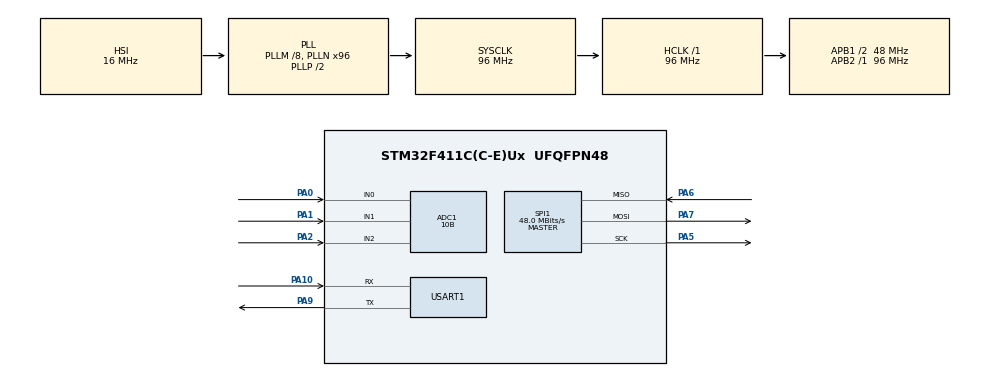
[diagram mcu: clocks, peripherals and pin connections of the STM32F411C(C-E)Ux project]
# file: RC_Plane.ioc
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ADC1.Channel-2\#ChannelRegularConversion=ADC_CHANNEL_0
ADC1.Channel-3\#ChannelRegularConversion=ADC_CHANNEL_1
ADC1.Channel-4\#ChannelRegularConversion=ADC_CHANNEL_2
ADC1.ContinuousConvMode=ENABLE
ADC1.DMAContinuousRequests=ENABLE
ADC1.EOCSelection=ADC_EOC_SEQ_CONV
ADC1.NbrOfConversion=3
ADC1.NbrOfConversionFlag=1
ADC1.Rank-2\#ChannelRegularConversion=1
ADC1.Rank-3\#ChannelRegularConversion=2
ADC1.Rank-4\#ChannelRegularConversion=3
ADC1.Resolution=ADC_RESOLUTION_10B
ADC1.SamplingTime-2\#ChannelRegularConversion=ADC_SAMPLETIME_84CYCLES
ADC1.SamplingTime-3\#ChannelRegularConversion=ADC_SAMPLETIME_84CYCLES
ADC1.SamplingTime-4\#ChannelRegularConversion=ADC_SAMPLETIME_84CYCLES
ADC1.ScanConvMode=ENABLE
ADC1.master=1
Dma.ADC1.0.Direction=DMA_PERIPH_TO_MEMORY
Dma.ADC1.0.FIFOMode=DMA_FIFOMODE_DISABLE
Dma.ADC1.0.Instance=DMA2_Stream0
Dma.ADC1.0.MemDataAlignment=DMA_MDATAALIGN_HALFWORD
Dma.ADC1.0.MemInc=DMA_MINC_ENABLE
Dma.ADC1.0.Mode=DMA_CIRCULAR
Dma.ADC1.0.PeriphDataAlignment=DMA_PDATAALIGN_HALFWORD
Dma.ADC1.0.PeriphInc=DMA_PINC_DISABLE
Dma.ADC1.0.Priority=DMA_PRIORITY_LOW
Dma.Request0=ADC1
FREERTOS.Tasks01=defaultTask,0,128,StartDefaultTask,Default,NULL,Dynamic,NULL,NULL
Mcu.Family=STM32F4
Mcu.Name=STM32F411C(C-E)Ux
Mcu.Package=UFQFPN48
NVIC.DMA2_Stream0_IRQn=true\:5\:0\:false\:false\:true\:true\:false\:true\:true
NVIC.PriorityGroup=NVIC_PRIORITYGROUP_4
NVIC.TIM1_TRG_COM_TIM11_IRQn=true\:15\:0\:false\:false\:true\:false\:false\:true\:true
NVIC.TimeBase=TIM1_TRG_COM_TIM11_IRQn
NVIC.TimeBaseIP=TIM11
PA0-WKUP.Signal=ADCx_IN0
PA1.Signal=ADCx_IN1
PA10.Mode=Asynchronous
PA10.Signal=USART1_RX
PA13.Mode=Serial_Wire
PA13.Signal=SYS_JTMS-SWDIO
PA14.Mode=Serial_Wire
PA14.Signal=SYS_JTCK-SWCLK
PA2.Signal=ADCx_IN2
PA5.Mode=Full_Duplex_Master
PA5.Signal=SPI1_SCK
PA6.Mode=Full_Duplex_Master
PA6.Signal=SPI1_MISO
PA7.Mode=Full_Duplex_Master
PA7.Signal=SPI1_MOSI
PA9.Mode=Asynchronous
PA9.Signal=USART1_TX
PH0\ -\ OSC_IN.Mode=HSE-External-Oscillator
PH0\ -\ OSC_IN.Signal=RCC_OSC_IN
PH1\ -\ OSC_OUT.Mode=HSE-External-Oscillator
PH1\ -\ OSC_OUT.Signal=RCC_OSC_OUT
ProjectManager.HeapSize=0x200
ProjectManager.StackSize=0x400
ProjectManager.TargetToolchain=CMake
RCC.48MHZClocksFreq_Value=48000000
RCC.AHBFreq_Value=96000000
RCC.APB1CLKDivider=RCC_HCLK_DIV2
RCC.APB1Freq_Value=48000000
RCC.APB1TimFreq_Value=96000000
RCC.APB2Freq_Value=96000000
RCC.APB2TimFreq_Value=96000000
RCC.CortexFreq_Value=96000000
RCC.HCLKFreq_Value=96000000
RCC.HSE_VALUE=25000000
RCC.HSI_VALUE=16000000
RCC.LSE_VALUE=32768
RCC.PLLM=8
RCC.PLLN=96
RCC.SYSCLKFreq_VALUE=96000000
RCC.SYSCLKSource=RCC_SYSCLKSOURCE_PLLCLK
RCC.VCOOutputFreq_Value=192000000
SH.ADCx_IN0.0=ADC1_IN0,IN0
SH.ADCx_IN1.0=ADC1_IN1,IN1
SH.ADCx_IN2.0=ADC1_IN2,IN2
SPI1.CalculateBaudRate=48.0 MBits/s
SPI1.Direction=SPI_DIRECTION_2LINES
SPI1.Mode=SPI_MODE_MASTER
SPI1.VirtualType=VM_MASTER
USART1.VirtualMode=VM_ASYNC
VP_FREERTOS_VS_CMSIS_V1.Mode=CMSIS_V1
VP_SYS_VS_tim11.Mode=TIM11
board=custom

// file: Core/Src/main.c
/* USER CODE BEGIN Header */
/**
  ******************************************************************************
  * @file           : main.c
  * @brief          : Main program body
  ******************************************************************************
  * @attention
  *
  * Copyright (c) 2026 STMicroelectronics.
  * All rights reserved.
  *
  * This software is licensed under terms that can be found in the LICENSE file
  * in the root directory of this software component.
  * If no LICENSE file comes with this software, it is provided AS-IS.
  *
  ******************************************************************************
  */
/* USER CODE END Header */
#include "main.h"
#include "cmsis_os.h"
#include "adc.h"
#include "dma.h"
#include "spi.h"
#include "usart.h"
#include "gpio.h"

/* USER CODE BEGIN PV */
volatile uint16_t joystick_vals[3];
/* USER CODE END PV */

void SystemClock_Config(void);
void MX_FREERTOS_Init(void);

int main(void)
{

  /* MCU Configuration--------------------------------------------------------*/

  /* Reset of all peripherals, Initializes the Flash interface and the Systick. */
  HAL_Init();

  /* Configure the system clock */
  SystemClock_Config();

  /* Initialize all configured peripherals */
  MX_GPIO_Init();
  MX_DMA_Init();
  MX_ADC1_Init();
  MX_SPI1_Init();
  MX_USART1_UART_Init();

  /* Call init function for freertos objects (in cmsis_os2.c) */
  MX_FREERTOS_Init();

  /* Start scheduler */
  osKernelStart();

  /* We should never get here as control is now taken by the scheduler */

  /* Infinite loop */
  while (1)
  {

  }
}

void SystemClock_Config(void)
{
  RCC_OscInitTypeDef RCC_OscInitStruct = {0};
  RCC_ClkInitTypeDef RCC_ClkInitStruct = {0};

  /** Configure the main internal regulator output voltage
  */
  __HAL_RCC_PWR_CLK_ENABLE();
  __HAL_PWR_VOLTAGESCALING_CONFIG(PWR_REGULATOR_VOLTAGE_SCALE1);

  /** Initializes the RCC Oscillators according to the specified parameters
  * in the RCC_OscInitTypeDef structure.
  */
  RCC_OscInitStruct.OscillatorType = RCC_OSCILLATORTYPE_HSI;
  RCC_OscInitStruct.HSIState = RCC_HSI_ON;
  RCC_OscInitStruct.HSICalibrationValue = RCC_HSICALIBRATION_DEFAULT;
  RCC_OscInitStruct.PLL.PLLState = RCC_PLL_ON;
  RCC_OscInitStruct.PLL.PLLSource = RCC_PLLSOURCE_HSI;
  RCC_OscInitStruct.PLL.PLLM = 8;
  RCC_OscInitStruct.PLL.PLLN = 96;
  RCC_OscInitStruct.PLL.PLLP = RCC_PLLP_DIV2;
  RCC_OscInitStruct.PLL.PLLQ = 4;
  if (HAL_RCC_OscConfig(&RCC_OscInitStruct) != HAL_OK)
  {
    Error_Handler();
  }

  /** Initializes the CPU, AHB and APB buses clocks
  */
  RCC_ClkInitStruct.ClockType = RCC_CLOCKTYPE_HCLK|RCC_CLOCKTYPE_SYSCLK
                              |RCC_CLOCKTYPE_PCLK1|RCC_CLOCKTYPE_PCLK2;
  RCC_ClkInitStruct.SYSCLKSource = RCC_SYSCLKSOURCE_PLLCLK;
  RCC_ClkInitStruct.AHBCLKDivider = RCC_SYSCLK_DIV1;
  RCC_ClkInitStruct.APB1CLKDivider = RCC_HCLK_DIV2;
  RCC_ClkInitStruct.APB2CLKDivider = RCC_HCLK_DIV1;

  if (HAL_RCC_ClockConfig(&RCC_ClkInitStruct, FLASH_LATENCY_3) != HAL_OK)
  {
    Error_Handler();
  }
}

void HAL_TIM_PeriodElapsedCallback(TIM_HandleTypeDef *htim)
{
  if (htim->Instance == TIM11)
  {
    HAL_IncTick();
  }
}

void Error_Handler(void)
{
  __disable_irq();
  while (1)
  {
  }
}

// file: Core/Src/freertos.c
/* USER CODE BEGIN Header */
/**
  ******************************************************************************
  * File Name          : freertos.c
  * Description        : Code for freertos applications
  ******************************************************************************
  * @attention
  *
  * Copyright (c) 2026 STMicroelectronics.
  * All rights reserved.
  *
  * This software is licensed under terms that can be found in the LICENSE file
  * in the root directory of this software component.
  * If no LICENSE file comes with this software, it is provided AS-IS.
  *
  ******************************************************************************
  */
/* USER CODE END Header */

#include "FreeRTOS.h"
#include "adc.h"
#include "joysticks.h"
#include "task.h"
#include "main.h"
#include "cmsis_os.h"
#include <stdint.h>
#include <stdio.h>

osThreadId defaultTaskHandle;

void StartDefaultTask(void const * argument);

void MX_FREERTOS_Init(void); /* (MISRA C 2004 rule 8.1) */

/* GetIdleTaskMemory prototype (linked to static allocation support) */
void vApplicationGetIdleTaskMemory( StaticTask_t **ppxIdleTaskTCBBuffer, StackType_t **ppxIdleTaskStackBuffer, uint32_t *pulIdleTaskStackSize );

/* USER CODE BEGIN GET_IDLE_TASK_MEMORY */
static StaticTask_t xIdleTaskTCBBuffer;
static StackType_t xIdleStack[configMINIMAL_STACK_SIZE];

void vApplicationGetIdleTaskMemory( StaticTask_t **ppxIdleTaskTCBBuffer, StackType_t **ppxIdleTaskStackBuffer, uint32_t *pulIdleTaskStackSize )
{
  *ppxIdleTaskTCBBuffer = &xIdleTaskTCBBuffer;
  *ppxIdleTaskStackBuffer = &xIdleStack[0];
  *pulIdleTaskStackSize = configMINIMAL_STACK_SIZE;
  /* place for user code */
}
/* USER CODE END GET_IDLE_TASK_MEMORY */

void MX_FREERTOS_Init(void) {

  /* Create the thread(s) */
  /* definition and creation of defaultTask */
  osThreadDef(defaultTask, StartDefaultTask, osPriorityNormal, 0, 128);
  defaultTaskHandle = osThreadCreate(osThread(defaultTask), NULL);

}

void StartDefaultTask(void const * argument)
{
  /* USER CODE BEGIN StartDefaultTask */
  plane_ctrls_pckt_t plane_ctrls_pckt = {
    .throttle = 512,
    .roll = 512,
    .pitch = 512
  };

  joysticks_adc_dma_start();
  /* Infinite loop */
  for(;;)
  {
    joysticks_get(&plane_ctrls_pckt);
    printf("Hello World\n");
    osDelay(10);
  }
  /* USER CODE END StartDefaultTask */
}
